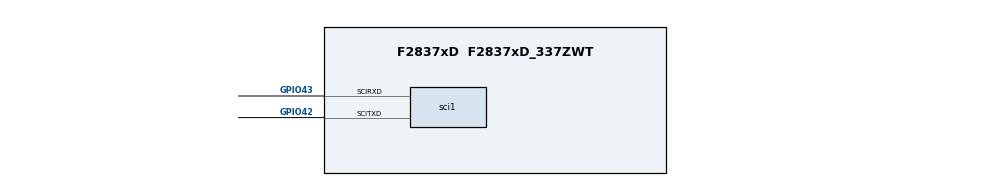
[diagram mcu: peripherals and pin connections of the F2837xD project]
/**
 * @cliArgs --board "/boards/LAUNCHXL_F28379D" --device "F2837xD" --part "F2837xD_337ZWT" --package "F2837xD_337ZWT" --context "CPU1" --product "C2000WARE@26.00.00.00"
 * @versions {"tool":"1.27.1+4634"}
 */

/**
 * Import the modules used in this configuration.
 */
const adc       = scripting.addModule("/driverlib/adc.js", {}, false);
const adc1      = adc.addInstance();
const cputimer  = scripting.addModule("/driverlib/cputimer.js", {}, false);
const cputimer1 = cputimer.addInstance();
const cputimer2 = cputimer.addInstance();
const dac       = scripting.addModule("/driverlib/dac.js", {}, false);
const dac1      = dac.addInstance();
const sci       = scripting.addModule("/driverlib/sci.js", {}, false);
const sci1      = sci.addInstance();

/**
 * Write custom configuration values to the imported modules.
 */
adc1.$name                   = "ADC0";
adc1.adcClockPrescaler       = "ADC_CLK_DIV_4_0";
adc1.enabledSOCs             = ["ADC_SOC_NUMBER0"];
adc1.soc0SampleWindow        = 15;
adc1.interruptPulseMode      = "ADC_PULSE_END_OF_CONV";
adc1.enabledInts             = ["ADC_INT_NUMBER1"];
adc1.enableInterrupt1        = true;
adc1.registerInterrupts      = ["1"];
adc1.soc0Trigger             = "ADC_TRIGGER_CPU1_TINT1";
adc1.adcInt1.enableInterrupt = true;

cputimer1.$name           = "myCPUTIMER0";
cputimer1.startTimer      = true;
cputimer1.enableInterrupt = true;
cputimer1.timerPeriod     = 39999;

cputimer2.$name                    = "myCPUTIMER1";
cputimer2.cputimerBase             = "CPUTIMER1_BASE";
cputimer2.registerInterrupts       = true;
cputimer2.enableInterrupt          = true;
cputimer2.startTimer               = true;
cputimer2.timerPeriod              = 7999999;
cputimer2.timerInt.enableInterrupt = true;

dac1.$name            = "DAC0";
dac1.referenceVoltage = "DAC_REF_ADC_VREFHI";
dac1.enableOutput     = true;
dac1.dacBase          = "DACB_BASE";

sci1.$name                      = "SCI0";
sci1.selectRegisteredInterrupts = ["registerRxInt"];
sci1.enabledFIFOInterrupts      = ["SCI_INT_RXFF"];
sci1.rxFifo                     = "SCI_FIFO_RX1";
sci1.txFifo                     = "SCI_FIFO_TX1";
sci1.sci.scirxdPin.$assign      = "GPIO43";
sci1.sci.scitxdPin.$assign      = "GPIO42";
sci1.rxQual.$name               = "myGPIOQUAL0";
sci1.txQual.$name               = "myGPIOQUAL1";
sci1.sciRXInt.enableInterrupt   = true;

/**
 * Pinmux solution for unlocked pins/peripherals. This ensures that minor changes to the automatic solver in a future
 * version of the tool will not impact the pinmux you originally saw.  These lines can be completely deleted in order to
 * re-solve from scratch.
 */
sci1.sci.$suggestSolution = "SCIA";
